# ATmega162 register map
Vendor: Atmel; File version: 1.0
CPU: other r0p0, little endian, no MPU, no FPU, 4 interrupt priority bits
Registers are 8-bit, read-write, reset 0x0 unless marked. A register's access mark holds for its fields unless they carry their own. Offsets are from the block's base; lines under a group give offsets from that group; [hi:lo] are bit positions; {n}, {i} and the like mark numbered series; 'fields as' and 'values as' point back to an identical list; <NAME> marks a mode.

## Memory map
0x00000000 FUSE size 0x3 — Fuses
0x00000000 LOCKBIT size 0x1 — Lockbits
0x00000020 USART1 blocks up to offset 0x3D — USART
0x00000024 CPU blocks up to offset 0x3E — CPU Registers
0x00000024 JTAG blocks up to offset 0x31 — JTAG Interface
0x00000025 PORTE size 0x3 — I/O Port
0x00000028 AC size 0x1 — Analog Comparator
0x00000029 USART0 blocks up to offset 0x18 — USART
0x0000002D SPI size 0x3 — Serial Peripheral Interface
0x00000030 PORTD size 0x3 — I/O Port
0x00000033 PORTC size 0x3 — I/O Port
0x00000036 PORTB size 0x3 — I/O Port
0x00000039 PORTA size 0x3 — I/O Port
0x0000003C EEPROM size 0x4
0x00000041 WDT size 0x1 — Watchdog Timer
0x00000042 TC2 blocks up to offset 0x18 — Timer/Counter, 8-bit Async
0x00000044 TC1 blocks up to offset 0x16 — Timer/Counter, 16-bit
0x00000051 TC0 blocks up to offset 0x9 — Timer/Counter, 8-bit
0x00000055 EXINT blocks up to offset 0x18 — External Interrupts
0x00000057 BOOT_LOAD size 0x1 — Bootloader
0x0000007C TC3 blocks up to offset 0x10 — Timer/Counter, 16-bit

## Interrupts
0 RESET (CPU) — External Pin,Power-on Reset,Brown-out Reset,Watchdog Reset,and JTAG AVR Reset. See Datasheet.
1 INT0 (CPU) — External Interrupt Request 0
2 INT1 (CPU) — External Interrupt Request 1
3 INT2 (CPU) — External Interrupt Request 2
4 PCINT0 (CPU) — Pin Change Interrupt Request 0
5 PCINT1 (CPU) — Pin Change Interrupt Request 1
6 TIMER3_CAPT (CPU) — Timer/Counter3 Capture Event
7 TIMER3_COMPA (CPU) — Timer/Counter3 Compare Match A
8 TIMER3_COMPB (CPU) — Timer/Counter3 Compare Match B
9 TIMER3_OVF (CPU) — Timer/Counter3 Overflow
10 TIMER2_COMP (CPU) — Timer/Counter2 Compare Match
11 TIMER2_OVF (CPU) — Timer/Counter2 Overflow
12 TIMER1_CAPT (CPU) — Timer/Counter1 Capture Event
13 TIMER1_COMPA (CPU) — Timer/Counter1 Compare Match A
14 TIMER1_COMPB (CPU) — Timer/Counter Compare Match B
15 TIMER1_OVF (CPU) — Timer/Counter1 Overflow
16 TIMER0_COMP (CPU) — Timer/Counter0 Compare Match
17 TIMER0_OVF (CPU) — Timer/Counter0 Overflow
18 SPI_STC (CPU) — SPI Serial Transfer Complete
19 USART0_RXC (CPU) — USART0, Rx Complete
20 USART1_RXC (CPU) — USART1, Rx Complete
21 USART0_UDRE (CPU) — USART0 Data register Empty
22 USART1_UDRE (CPU) — USART1, Data register Empty
23 USART0_TXC (CPU) — USART0, Tx Complete
24 USART1_TXC (CPU) — USART1, Tx Complete
25 EE_RDY (CPU) — EEPROM Ready
26 ANA_COMP (CPU) — Analog Comparator
27 SPM_RDY (CPU) — Store Program Memory Read

## AC — Analog Comparator
Base 0x00000028
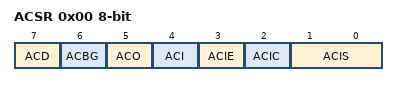
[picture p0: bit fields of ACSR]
0x00 ACSR — Analog Comparator Control And Status Register
  [7] ACD — Analog Comparator Disable
  [6] ACBG — Analog Comparator Bandgap Select
  [5] ACO — Analog Compare Output
  [4] ACI — Analog Comparator Interrupt Flag
  [3] ACIE — Analog Comparator Interrupt Enable
  [2] ACIC — Analog Comparator Input Capture Enable
  [1:0] ACIS — Analog Comparator Interrupt Mode Select bits
    0=Interrupt on Toggle; 2=Interrupt on Falling Edge; 3=Interrupt on Rising Edge

## BOOT_LOAD — Bootloader
Base 0x00000057
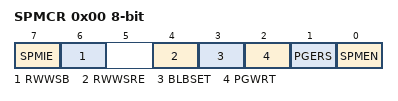
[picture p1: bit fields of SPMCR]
0x00 SPMCR — Store Program Memory Control Register
  [7] SPMIE — SPM Interrupt Enable
  [6] RWWSB — Read While Write Section Busy
  [4] RWWSRE — Read While Write secion read enable
  [3] BLBSET — Boot Lock Bit Set
  [2] PGWRT — Page Write
  [1] PGERS — Page Erase
  [0] SPMEN — Store Program Memory Enable

## CPU — CPU Registers
Base 0x00000024
0x00 OSCCAL — Oscillator Calibration Value
  [7:0] OSCCAL — Oscillator Calibration
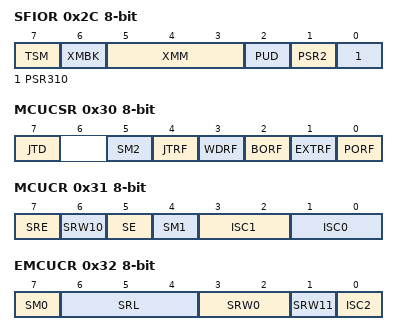
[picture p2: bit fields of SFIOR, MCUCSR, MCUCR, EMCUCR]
0x2C SFIOR — Special Function IO Register
  [7] TSM — Timer/Counter Synchronization Mode
  [6] XMBK — External Memory Bus Keeper Enable
  [5:3] XMM — External Memory High Mask Bits
  [2] PUD — Pull-up Disable
  [1] PSR2 — Prescaler Reset Timer/Counter2
  [0] PSR310 — Prescaler Reset Timer/Counter3, Timer/Counter1 and Timer/Counter0
0x30 MCUCSR — MCU Control And Status Register
  [7] JTD — JTAG Interface Disable
  [5] SM2 — Sleep Mode Select Bit 2
  [4] JTRF — JTAG Reset Flag
  [3] WDRF — Watchdog Reset Flag
  [2] BORF — Brown-out Reset Flag
  [1] EXTRF — External Reset Flag
  [0] PORF — Power-on reset flag
0x31 MCUCR — MCU Control Register
  [7] SRE — External SRAM Enable
  [6] SRW10 — External SRAM Wait State Select
  [5] SE — Sleep Enable
  [4] SM1 — Sleep Mode Select
  [3:2] ISC1 — Interrupt Sense Control 1 bits
    0=Low Level of INTX; 1=Any Logical Change in INTX; 2=Falling Edge of INTX; 3=Rising Edge of INTX
  [1:0] ISC0 — Interrupt Sense Control 0 bits
    values as ISC1
0x32 EMCUCR — Extended MCU Control Register
  [7] SM0 — Sleep mode Select Bit 0
  [6:4] SRL — Wait State Sector Limit Bits
    0=LS = N/A, US = 0x1100 - 0xFFFF; 1=LS = 0x1100 - 0x1FFF, US = 0x2000 - 0xFFFF; 2=LS = 0x1100 - 0x3FFF, US = 0x4000 - 0xFFFF; 3=LS = 0x1100 - 0x5FFF, US = 0x6000 - 0xFFFF; 4=LS = 0x1100 - 0x7FFF, US = 0x8000 - 0xFFFF; 5=LS = 0x1100 - 0x9FFF, US = 0xA000 - 0xFFFF; 6=LS = 0x1100 - 0xBFFF, US = 0xC000 - 0xFFFF; 7=LS = 0x1100 - 0xDFFF, US = 0xE000 - 0xFFFF
  [3:2] SRW0 — Wait State Select Bit 1 for Lower Sector
    0=No wait-states; 1=Wait one cycle during read/write strobe; 2=Wait two cycles during read/write strobe; 3=Wait two cycles during read/write and wait one cycle before driving out new address
  [1] SRW11 — Wait State Select Bit 1 for Upper Sector
  [0] ISC2 — Interrupt Sense Control 2
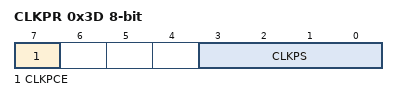
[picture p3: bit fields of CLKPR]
0x3D CLKPR — Clock prescale register
  [7] CLKPCE — Clock Prescaler Change Enable
  [3:0] CLKPS — Clock Prescaler Select Bits
    0=1; 1=2; 2=4; 3=8; 4=16; 5=32; 6=64; 7=128; 8=256
